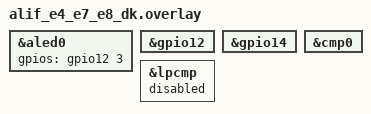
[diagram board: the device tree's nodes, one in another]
/* Copyright (C) 2025 Alif Semiconductor - All Rights Reserved.
 * Use, distribution and modification of this code is permitted under the
 * terms stated in the Alif Semiconductor Software License Agreement
 *
 * You should have received a copy of the Alif Semiconductor Software
 * License Agreement with this file. If not, please write to:
 * contact@alifsemi.com, or visit: https://alifsemi.com/license
 */

&aled0 {
	gpios = <&gpio12 3 GPIO_ACTIVE_HIGH>;
};

&gpio12 {
	status = "okay";
};

&gpio14 {
	status = "okay";
};

&cmp0 {
	status = "okay";
};

&lpcmp {
	status = "disabled";
};
